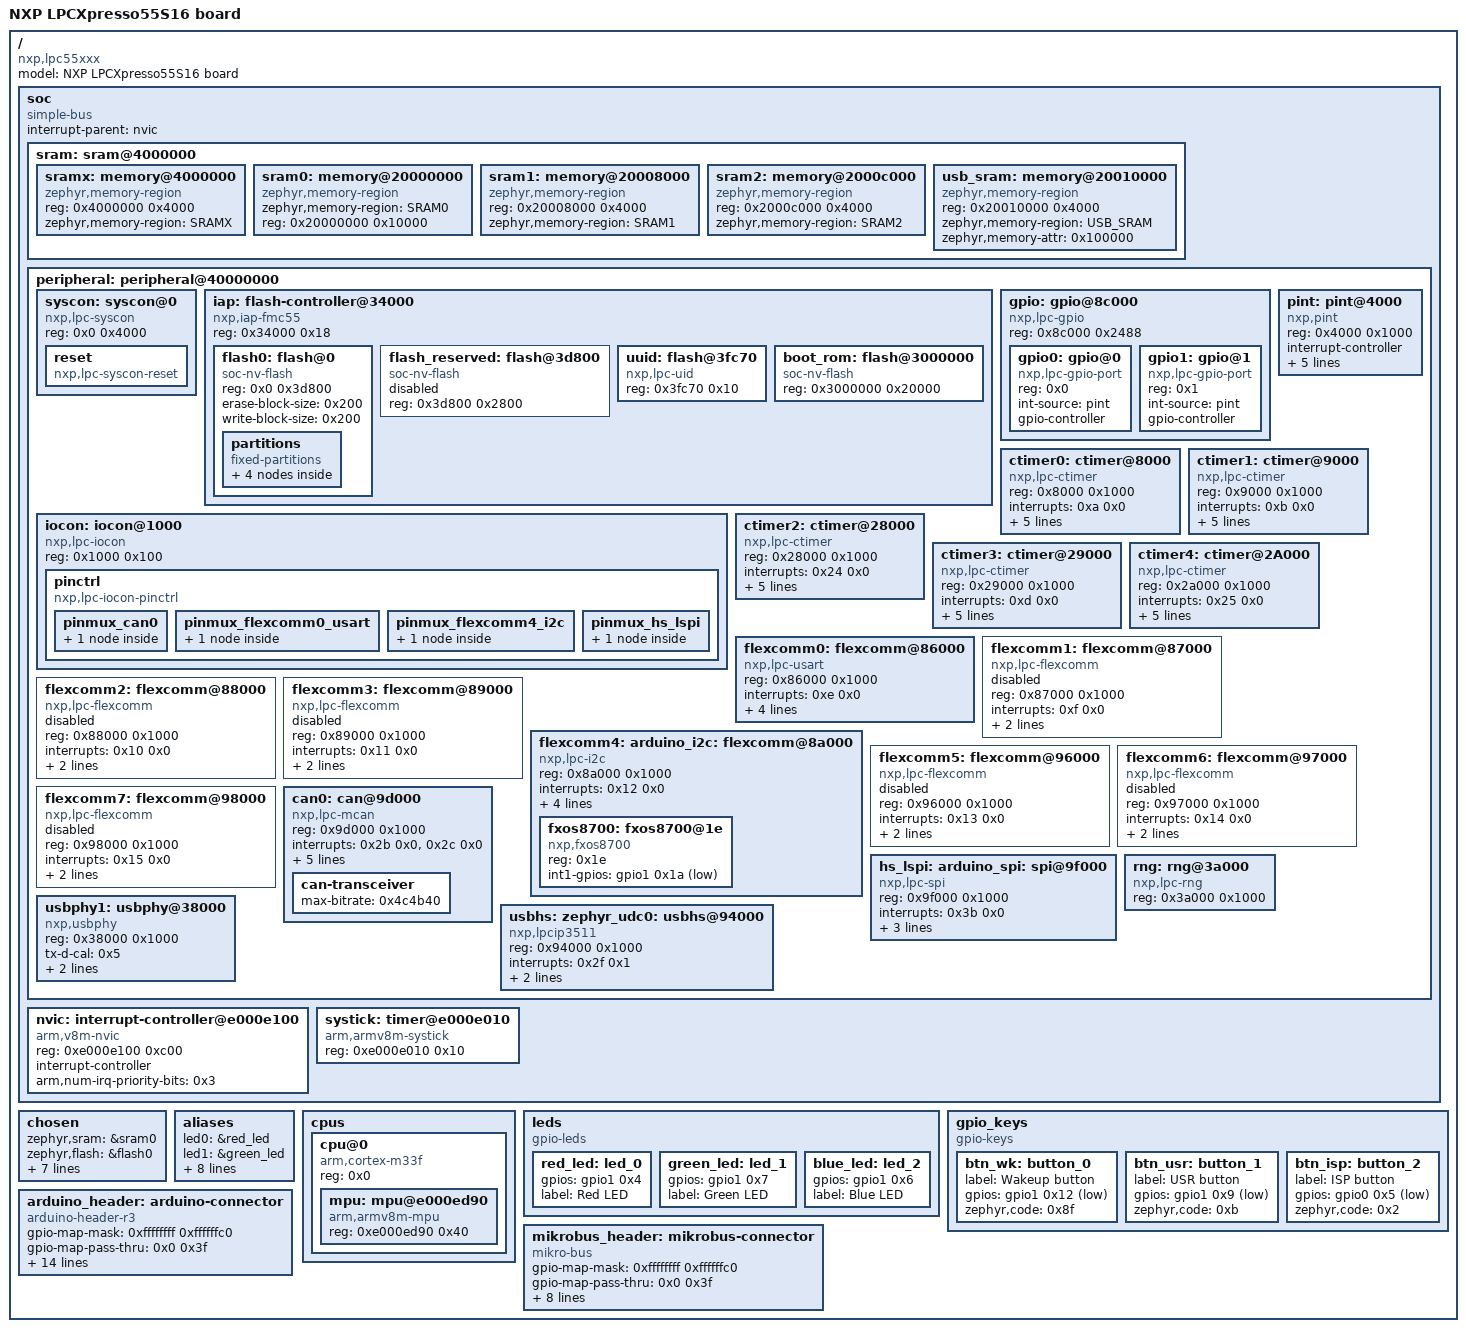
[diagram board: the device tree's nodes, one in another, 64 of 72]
/dts-v1/;

/* node '/' defined in zephyr/dts/arm/nxp/nxp_lpc55S16_ns.dtsi:7 */
/ {
	#address-cells = < 0x1 >;            /* in zephyr/dts/common/skeleton.dtsi:10 */
	#size-cells = < 0x1 >;               /* in zephyr/dts/common/skeleton.dtsi:11 */
	model = "NXP LPCXpresso55S16 board"; /* in zephyr/boards/nxp/lpcxpresso55s16/lpcxpresso55s16.dts:14 */
	compatible = "nxp,lpc55xxx",
	             "nxp,lpc";              /* in zephyr/boards/nxp/lpcxpresso55s16/lpcxpresso55s16.dts:15 */

	/* node '/soc' defined in zephyr/dts/arm/nxp/nxp_lpc55S16_ns.dtsi:8 */
	soc {
		#address-cells = < 0x1 >;     /* in zephyr/dts/arm/armv8-m.dtsi:7 */
		#size-cells = < 0x1 >;        /* in zephyr/dts/arm/armv8-m.dtsi:8 */
		compatible = "simple-bus";    /* in zephyr/dts/arm/armv8-m.dtsi:9 */
		interrupt-parent = < &nvic >; /* in zephyr/dts/arm/armv8-m.dtsi:10 */
		ranges;                       /* in zephyr/dts/arm/armv8-m.dtsi:11 */

		/* node '/soc/sram@4000000' defined in zephyr/dts/arm/nxp/nxp_lpc55S16_ns.dtsi:9 */
		sram: sram@4000000 {
			ranges = < 0x4000000 0x4000000 0x20000000 >; /* in zephyr/dts/arm/nxp/nxp_lpc55S16_ns.dtsi:10 */
			#address-cells = < 0x1 >;                    /* in zephyr/dts/arm/nxp/nxp_lpc55S1x_common.dtsi:36 */
			#size-cells = < 0x1 >;                       /* in zephyr/dts/arm/nxp/nxp_lpc55S1x_common.dtsi:37 */

			/* node '/soc/sram@4000000/memory@4000000' defined in zephyr/dts/arm/nxp/nxp_lpc55S1x_common.dtsi:39 */
			sramx: memory@4000000 {
				compatible = "zephyr,memory-region",
				             "mmio-sram";            /* in zephyr/dts/arm/nxp/nxp_lpc55S1x_common.dtsi:40 */
				reg = < 0x4000000 0x4000 >;          /* in zephyr/dts/arm/nxp/nxp_lpc55S1x_common.dtsi:41 */
				zephyr,memory-region = "SRAMX";      /* in zephyr/dts/arm/nxp/nxp_lpc55S1x_common.dtsi:42 */
			};

			/* node '/soc/sram@4000000/memory@20000000' defined in zephyr/dts/arm/nxp/nxp_lpc55S1x_common.dtsi:45 */
			sram0: memory@20000000 {
				compatible = "zephyr,memory-region",
				             "mmio-sram";            /* in zephyr/dts/arm/nxp/nxp_lpc55S1x_common.dtsi:46 */
				zephyr,memory-region = "SRAM0";      /* in zephyr/dts/arm/nxp/nxp_lpc55S1x_common.dtsi:48 */
				reg = < 0x20000000 0x10000 >;        /* in zephyr/boards/nxp/lpcxpresso55s16/lpcxpresso55s16.dts:24 */
			};

			/* node '/soc/sram@4000000/memory@20008000' defined in zephyr/dts/arm/nxp/nxp_lpc55S1x_common.dtsi:51 */
			sram1: memory@20008000 {
				compatible = "zephyr,memory-region",
				             "mmio-sram";            /* in zephyr/dts/arm/nxp/nxp_lpc55S1x_common.dtsi:52 */
				reg = < 0x20008000 0x4000 >;         /* in zephyr/dts/arm/nxp/nxp_lpc55S1x_common.dtsi:53 */
				zephyr,memory-region = "SRAM1";      /* in zephyr/dts/arm/nxp/nxp_lpc55S1x_common.dtsi:54 */
			};

			/* node '/soc/sram@4000000/memory@2000c000' defined in zephyr/dts/arm/nxp/nxp_lpc55S1x_common.dtsi:57 */
			sram2: memory@2000c000 {
				compatible = "zephyr,memory-region",
				             "mmio-sram";            /* in zephyr/dts/arm/nxp/nxp_lpc55S1x_common.dtsi:58 */
				reg = < 0x2000c000 0x4000 >;         /* in zephyr/dts/arm/nxp/nxp_lpc55S1x_common.dtsi:59 */
				zephyr,memory-region = "SRAM2";      /* in zephyr/dts/arm/nxp/nxp_lpc55S1x_common.dtsi:60 */
			};

			/* node '/soc/sram@4000000/memory@20010000' defined in zephyr/dts/arm/nxp/nxp_lpc55S1x_common.dtsi:63 */
			usb_sram: memory@20010000 {
				compatible = "zephyr,memory-region",
				             "mmio-sram";            /* in zephyr/dts/arm/nxp/nxp_lpc55S1x_common.dtsi:65 */
				reg = < 0x20010000 0x4000 >;         /* in zephyr/dts/arm/nxp/nxp_lpc55S1x_common.dtsi:66 */
				zephyr,memory-region = "USB_SRAM";   /* in zephyr/dts/arm/nxp/nxp_lpc55S1x_common.dtsi:67 */
				zephyr,memory-attr = < 0x100000 >;   /* in zephyr/dts/arm/nxp/nxp_lpc55S1x_common.dtsi:68 */
			};
		};

		/* node '/soc/peripheral@40000000' defined in zephyr/dts/arm/nxp/nxp_lpc55S16_ns.dtsi:13 */
		peripheral: peripheral@40000000 {
			ranges = < 0x0 0x40000000 0x10000000 >; /* in zephyr/dts/arm/nxp/nxp_lpc55S16_ns.dtsi:14 */
			#address-cells = < 0x1 >;               /* in zephyr/dts/arm/nxp/nxp_lpc55S1x_common.dtsi:73 */
			#size-cells = < 0x1 >;                  /* in zephyr/dts/arm/nxp/nxp_lpc55S1x_common.dtsi:74 */

			/* node '/soc/peripheral@40000000/syscon@0' defined in zephyr/dts/arm/nxp/nxp_lpc55S1x_common.dtsi:76 */
			syscon: syscon@0 {
				compatible = "nxp,lpc-syscon"; /* in zephyr/dts/arm/nxp/nxp_lpc55S1x_common.dtsi:77 */
				reg = < 0x0 0x4000 >;          /* in zephyr/dts/arm/nxp/nxp_lpc55S1x_common.dtsi:78 */
				#clock-cells = < 0x1 >;        /* in zephyr/dts/arm/nxp/nxp_lpc55S1x_common.dtsi:79 */
				phandle = < 0x2 >;             /* in zephyr/dts/arm/nxp/nxp_lpc55S1x_common.dtsi:171 */

				/* node '/soc/peripheral@40000000/syscon@0/reset' defined in zephyr/dts/arm/nxp/nxp_lpc55S1x_common.dtsi:81 */
				reset: reset {
					compatible = "nxp,lpc-syscon-reset"; /* in zephyr/dts/arm/nxp/nxp_lpc55S1x_common.dtsi:82 */
					#reset-cells = < 0x1 >;              /* in zephyr/dts/arm/nxp/nxp_lpc55S1x_common.dtsi:83 */
					phandle = < 0x3 >;                   /* in zephyr/dts/arm/nxp/nxp_lpc55S1x_common.dtsi:230 */
				};
			};

			/* node '/soc/peripheral@40000000/flash-controller@34000' defined in zephyr/dts/arm/nxp/nxp_lpc55S1x_common.dtsi:87 */
			iap: flash-controller@34000 {
				compatible = "nxp,iap-fmc55"; /* in zephyr/dts/arm/nxp/nxp_lpc55S1x_common.dtsi:88 */
				reg = < 0x34000 0x18 >;       /* in zephyr/dts/arm/nxp/nxp_lpc55S1x_common.dtsi:89 */
				#address-cells = < 0x1 >;     /* in zephyr/dts/arm/nxp/nxp_lpc55S1x_common.dtsi:90 */
				#size-cells = < 0x1 >;        /* in zephyr/dts/arm/nxp/nxp_lpc55S1x_common.dtsi:91 */
				status = "okay";              /* in zephyr/dts/arm/nxp/nxp_lpc55S16_ns.dtsi:22 */

				/* node '/soc/peripheral@40000000/flash-controller@34000/flash@0' defined in zephyr/dts/arm/nxp/nxp_lpc55S1x_common.dtsi:94 */
				flash0: flash@0 {
					compatible = "soc-nv-flash";  /* in zephyr/dts/arm/nxp/nxp_lpc55S1x_common.dtsi:95 */
					reg = < 0x0 0x3d800 >;        /* in zephyr/dts/arm/nxp/nxp_lpc55S1x_common.dtsi:96 */
					erase-block-size = < 0x200 >; /* in zephyr/dts/arm/nxp/nxp_lpc55S1x_common.dtsi:97 */
					write-block-size = < 0x200 >; /* in zephyr/dts/arm/nxp/nxp_lpc55S1x_common.dtsi:98 */

					/* node '/soc/peripheral@40000000/flash-controller@34000/flash@0/partitions' defined in zephyr/boards/nxp/lpcxpresso55s16/lpcxpresso55s16_common.dtsi:194 */
					partitions {
						compatible = "fixed-partitions"; /* in zephyr/boards/nxp/lpcxpresso55s16/lpcxpresso55s16_common.dtsi:195 */
						#address-cells = < 0x1 >;        /* in zephyr/boards/nxp/lpcxpresso55s16/lpcxpresso55s16_common.dtsi:196 */
						#size-cells = < 0x1 >;           /* in zephyr/boards/nxp/lpcxpresso55s16/lpcxpresso55s16_common.dtsi:197 */

						/* node '/soc/peripheral@40000000/flash-controller@34000/flash@0/partitions/partition@0' defined in zephyr/boards/nxp/lpcxpresso55s16/lpcxpresso55s16_common.dtsi:199 */
						boot_partition: partition@0 {
							label = "mcuboot";    /* in zephyr/boards/nxp/lpcxpresso55s16/lpcxpresso55s16_common.dtsi:200 */
							reg = < 0x0 0x8000 >; /* in zephyr/boards/nxp/lpcxpresso55s16/lpcxpresso55s16_common.dtsi:201 */
						};

						/* node '/soc/peripheral@40000000/flash-controller@34000/flash@0/partitions/partition@8000' defined in zephyr/boards/nxp/lpcxpresso55s16/lpcxpresso55s16_common.dtsi:204 */
						slot0_partition: partition@8000 {
							label = "image-0";        /* in zephyr/boards/nxp/lpcxpresso55s16/lpcxpresso55s16_common.dtsi:205 */
							reg = < 0x8000 0x18000 >; /* in zephyr/boards/nxp/lpcxpresso55s16/lpcxpresso55s16_common.dtsi:206 */
						};

						/* node '/soc/peripheral@40000000/flash-controller@34000/flash@0/partitions/partition@20000' defined in zephyr/boards/nxp/lpcxpresso55s16/lpcxpresso55s16_common.dtsi:209 */
						slot1_partition: partition@20000 {
							label = "image-1";         /* in zephyr/boards/nxp/lpcxpresso55s16/lpcxpresso55s16_common.dtsi:210 */
							reg = < 0x20000 0x18000 >; /* in zephyr/boards/nxp/lpcxpresso55s16/lpcxpresso55s16_common.dtsi:211 */
						};

						/* node '/soc/peripheral@40000000/flash-controller@34000/flash@0/partitions/partition@38000' defined in zephyr/boards/nxp/lpcxpresso55s16/lpcxpresso55s16_common.dtsi:214 */
						storage_partition: partition@38000 {
							label = "storage";        /* in zephyr/boards/nxp/lpcxpresso55s16/lpcxpresso55s16_common.dtsi:215 */
							reg = < 0x38000 0x5000 >; /* in zephyr/boards/nxp/lpcxpresso55s16/lpcxpresso55s16_common.dtsi:216 */
						};
					};
				};

				/* node '/soc/peripheral@40000000/flash-controller@34000/flash@3d800' defined in zephyr/dts/arm/nxp/nxp_lpc55S1x_common.dtsi:101 */
				flash_reserved: flash@3d800 {
					compatible = "soc-nv-flash"; /* in zephyr/dts/arm/nxp/nxp_lpc55S1x_common.dtsi:102 */
					reg = < 0x3d800 0x2800 >;    /* in zephyr/dts/arm/nxp/nxp_lpc55S1x_common.dtsi:103 */
					status = "disabled";         /* in zephyr/dts/arm/nxp/nxp_lpc55S1x_common.dtsi:104 */
				};

				/* node '/soc/peripheral@40000000/flash-controller@34000/flash@3fc70' defined in zephyr/dts/arm/nxp/nxp_lpc55S1x_common.dtsi:107 */
				uuid: flash@3fc70 {
					compatible = "nxp,lpc-uid"; /* in zephyr/dts/arm/nxp/nxp_lpc55S1x_common.dtsi:108 */
					reg = < 0x3fc70 0x10 >;     /* in zephyr/dts/arm/nxp/nxp_lpc55S1x_common.dtsi:109 */
				};

				/* node '/soc/peripheral@40000000/flash-controller@34000/flash@3000000' defined in zephyr/dts/arm/nxp/nxp_lpc55S1x_common.dtsi:112 */
				boot_rom: flash@3000000 {
					compatible = "soc-nv-flash"; /* in zephyr/dts/arm/nxp/nxp_lpc55S1x_common.dtsi:113 */
					reg = < 0x3000000 0x20000 >; /* in zephyr/dts/arm/nxp/nxp_lpc55S1x_common.dtsi:114 */
				};
			};

			/* node '/soc/peripheral@40000000/iocon@1000' defined in zephyr/dts/arm/nxp/nxp_lpc55S1x_common.dtsi:118 */
			iocon: iocon@1000 {
				compatible = "nxp,lpc-iocon";  /* in zephyr/dts/arm/nxp/nxp_lpc55S1x_common.dtsi:119 */
				reg = < 0x1000 0x100 >;        /* in zephyr/dts/arm/nxp/nxp_lpc55S1x_common.dtsi:120 */
				#address-cells = < 0x1 >;      /* in zephyr/dts/arm/nxp/nxp_lpc55S1x_common.dtsi:121 */
				#size-cells = < 0x1 >;         /* in zephyr/dts/arm/nxp/nxp_lpc55S1x_common.dtsi:122 */
				ranges = < 0x0 0x1000 0x100 >; /* in zephyr/dts/arm/nxp/nxp_lpc55S1x_common.dtsi:123 */

				/* node '/soc/peripheral@40000000/iocon@1000/pinctrl' defined in zephyr/dts/arm/nxp/nxp_lpc55S1x_common.dtsi:125 */
				pinctrl: pinctrl {
					compatible = "nxp,lpc-iocon-pinctrl"; /* in zephyr/dts/arm/nxp/nxp_lpc55S1x_common.dtsi:126 */

					/* node '/soc/peripheral@40000000/iocon@1000/pinctrl/pinmux_can0' defined in zephyr/boards/nxp/lpcxpresso55s16/lpcxpresso55s16-pinctrl.dtsi:12 */
					pinmux_can0: pinmux_can0 {
						phandle = < 0x7 >; /* in zephyr/boards/nxp/lpcxpresso55s16/lpcxpresso55s16_common.dtsi:159 */

						/* node '/soc/peripheral@40000000/iocon@1000/pinctrl/pinmux_can0/group0' defined in zephyr/boards/nxp/lpcxpresso55s16/lpcxpresso55s16-pinctrl.dtsi:13 */
						group0 {
							pinmux = < 0x3600009 >,
							         < 0x3b00009 >; /* in zephyr/boards/nxp/lpcxpresso55s16/lpcxpresso55s16-pinctrl.dtsi:14 */
							slew-rate = "standard"; /* in zephyr/boards/nxp/lpcxpresso55s16/lpcxpresso55s16-pinctrl.dtsi:16 */
						};
					};

					/* node '/soc/peripheral@40000000/iocon@1000/pinctrl/pinmux_flexcomm0_usart' defined in zephyr/boards/nxp/lpcxpresso55s16/lpcxpresso55s16-pinctrl.dtsi:20 */
					pinmux_flexcomm0_usart: pinmux_flexcomm0_usart {
						phandle = < 0x4 >; /* in zephyr/boards/nxp/lpcxpresso55s16/lpcxpresso55s16_common.dtsi:137 */

						/* node '/soc/peripheral@40000000/iocon@1000/pinctrl/pinmux_flexcomm0_usart/group0' defined in zephyr/boards/nxp/lpcxpresso55s16/lpcxpresso55s16-pinctrl.dtsi:21 */
						group0 {
							pinmux = < 0x1d00001 >,
							         < 0x1e00001 >; /* in zephyr/boards/nxp/lpcxpresso55s16/lpcxpresso55s16-pinctrl.dtsi:22 */
							slew-rate = "standard"; /* in zephyr/boards/nxp/lpcxpresso55s16/lpcxpresso55s16-pinctrl.dtsi:24 */
						};
					};

					/* node '/soc/peripheral@40000000/iocon@1000/pinctrl/pinmux_flexcomm4_i2c' defined in zephyr/boards/nxp/lpcxpresso55s16/lpcxpresso55s16-pinctrl.dtsi:28 */
					pinmux_flexcomm4_i2c: pinmux_flexcomm4_i2c {
						phandle = < 0x5 >; /* in zephyr/boards/nxp/lpcxpresso55s16/lpcxpresso55s16_common.dtsi:147 */

						/* node '/soc/peripheral@40000000/iocon@1000/pinctrl/pinmux_flexcomm4_i2c/group0' defined in zephyr/boards/nxp/lpcxpresso55s16/lpcxpresso55s16-pinctrl.dtsi:29 */
						group0 {
							pinmux = < 0x3400005 >,
							         < 0x3500005 >; /* in zephyr/boards/nxp/lpcxpresso55s16/lpcxpresso55s16-pinctrl.dtsi:30 */
							slew-rate = "standard"; /* in zephyr/boards/nxp/lpcxpresso55s16/lpcxpresso55s16-pinctrl.dtsi:32 */
						};
					};

					/* node '/soc/peripheral@40000000/iocon@1000/pinctrl/pinmux_hs_lspi' defined in zephyr/boards/nxp/lpcxpresso55s16/lpcxpresso55s16-pinctrl.dtsi:36 */
					pinmux_hs_lspi: pinmux_hs_lspi {
						phandle = < 0x8 >; /* in zephyr/boards/nxp/lpcxpresso55s16/lpcxpresso55s16_common.dtsi:169 */

						/* node '/soc/peripheral@40000000/iocon@1000/pinctrl/pinmux_hs_lspi/group0' defined in zephyr/boards/nxp/lpcxpresso55s16/lpcxpresso55s16-pinctrl.dtsi:37 */
						group0 {
							pinmux = < 0x1a00009 >,
							         < 0x2100005 >,
							         < 0x2200006 >,
							         < 0x2300006 >; /* in zephyr/boards/nxp/lpcxpresso55s16/lpcxpresso55s16-pinctrl.dtsi:38 */
							bias-pull-up;           /* in zephyr/boards/nxp/lpcxpresso55s16/lpcxpresso55s16-pinctrl.dtsi:42 */
							slew-rate = "standard"; /* in zephyr/boards/nxp/lpcxpresso55s16/lpcxpresso55s16-pinctrl.dtsi:43 */
						};
					};
				};
			};

			/* node '/soc/peripheral@40000000/gpio@8c000' defined in zephyr/dts/arm/nxp/nxp_lpc55S1x_common.dtsi:130 */
			gpio: gpio@8c000 {
				compatible = "nxp,lpc-gpio"; /* in zephyr/dts/arm/nxp/nxp_lpc55S1x_common.dtsi:131 */
				reg = < 0x8c000 0x2488 >;    /* in zephyr/dts/arm/nxp/nxp_lpc55S1x_common.dtsi:132 */
				#address-cells = < 0x1 >;    /* in zephyr/dts/arm/nxp/nxp_lpc55S1x_common.dtsi:133 */
				#size-cells = < 0x0 >;       /* in zephyr/dts/arm/nxp/nxp_lpc55S1x_common.dtsi:134 */

				/* node '/soc/peripheral@40000000/gpio@8c000/gpio@0' defined in zephyr/dts/arm/nxp/nxp_lpc55S1x_common.dtsi:136 */
				gpio0: gpio@0 {
					compatible = "nxp,lpc-gpio-port"; /* in zephyr/dts/arm/nxp/nxp_lpc55S1x_common.dtsi:137 */
					reg = < 0x0 >;                    /* in zephyr/dts/arm/nxp/nxp_lpc55S1x_common.dtsi:138 */
					int-source = "pint";              /* in zephyr/dts/arm/nxp/nxp_lpc55S1x_common.dtsi:139 */
					gpio-controller;                  /* in zephyr/dts/arm/nxp/nxp_lpc55S1x_common.dtsi:140 */
					#gpio-cells = < 0x2 >;            /* in zephyr/dts/arm/nxp/nxp_lpc55S1x_common.dtsi:141 */
					phandle = < 0xa >;                /* in zephyr/boards/nxp/lpcxpresso55s16/lpcxpresso55s16_common.dtsi:74 */
				};

				/* node '/soc/peripheral@40000000/gpio@8c000/gpio@1' defined in zephyr/dts/arm/nxp/nxp_lpc55S1x_common.dtsi:144 */
				gpio1: gpio@1 {
					compatible = "nxp,lpc-gpio-port"; /* in zephyr/dts/arm/nxp/nxp_lpc55S1x_common.dtsi:145 */
					reg = < 0x1 >;                    /* in zephyr/dts/arm/nxp/nxp_lpc55S1x_common.dtsi:146 */
					int-source = "pint";              /* in zephyr/dts/arm/nxp/nxp_lpc55S1x_common.dtsi:147 */
					gpio-controller;                  /* in zephyr/dts/arm/nxp/nxp_lpc55S1x_common.dtsi:148 */
					#gpio-cells = < 0x2 >;            /* in zephyr/dts/arm/nxp/nxp_lpc55S1x_common.dtsi:149 */
					phandle = < 0x6 >;                /* in zephyr/boards/nxp/lpcxpresso55s16/lpcxpresso55s16_common.dtsi:153 */
				};
			};

			/* node '/soc/peripheral@40000000/pint@4000' defined in zephyr/dts/arm/nxp/nxp_lpc55S1x_common.dtsi:153 */
			pint: pint@4000 {
				compatible = "nxp,pint";    /* in zephyr/dts/arm/nxp/nxp_lpc55S1x_common.dtsi:154 */
				reg = < 0x4000 0x1000 >;    /* in zephyr/dts/arm/nxp/nxp_lpc55S1x_common.dtsi:155 */
				interrupt-controller;       /* in zephyr/dts/arm/nxp/nxp_lpc55S1x_common.dtsi:156 */
				#interrupt-cells = < 0x1 >; /* in zephyr/dts/arm/nxp/nxp_lpc55S1x_common.dtsi:157 */
				#address-cells = < 0x0 >;   /* in zephyr/dts/arm/nxp/nxp_lpc55S1x_common.dtsi:158 */
				interrupts = < 0x4 0x2 >,
				             < 0x5 0x2 >,
				             < 0x6 0x2 >,
				             < 0x7 0x2 >,
				             < 0x20 0x2 >,
				             < 0x21 0x2 >,
				             < 0x22 0x2 >,
				             < 0x23 0x2 >;  /* in zephyr/dts/arm/nxp/nxp_lpc55S1x_common.dtsi:159 */
				num-lines = < 0x8 >;        /* in zephyr/dts/arm/nxp/nxp_lpc55S1x_common.dtsi:161 */
				num-inputs = < 0x40 >;      /* in zephyr/dts/arm/nxp/nxp_lpc55S1x_common.dtsi:162 */
			};

			/* node '/soc/peripheral@40000000/ctimer@8000' defined in zephyr/dts/arm/nxp/nxp_lpc55S1x_common.dtsi:165 */
			ctimer0: ctimer@8000 {
				compatible = "nxp,lpc-ctimer"; /* in zephyr/dts/arm/nxp/nxp_lpc55S1x_common.dtsi:166 */
				reg = < 0x8000 0x1000 >;       /* in zephyr/dts/arm/nxp/nxp_lpc55S1x_common.dtsi:167 */
				interrupts = < 0xa 0x0 >;      /* in zephyr/dts/arm/nxp/nxp_lpc55S1x_common.dtsi:168 */
				clk-source = < 0x3 >;          /* in zephyr/dts/arm/nxp/nxp_lpc55S1x_common.dtsi:170 */
				clocks = < &syscon 0x0 >;      /* in zephyr/dts/arm/nxp/nxp_lpc55S1x_common.dtsi:171 */
				mode = < 0x0 >;                /* in zephyr/dts/arm/nxp/nxp_lpc55S1x_common.dtsi:172 */
				input = < 0x0 >;               /* in zephyr/dts/arm/nxp/nxp_lpc55S1x_common.dtsi:173 */
				prescale = < 0x0 >;            /* in zephyr/dts/arm/nxp/nxp_lpc55S1x_common.dtsi:174 */
				status = "okay";               /* in zephyr/boards/nxp/lpcxpresso55s16/lpcxpresso55s16_common.dtsi:174 */
			};

			/* node '/soc/peripheral@40000000/ctimer@9000' defined in zephyr/dts/arm/nxp/nxp_lpc55S1x_common.dtsi:177 */
			ctimer1: ctimer@9000 {
				compatible = "nxp,lpc-ctimer"; /* in zephyr/dts/arm/nxp/nxp_lpc55S1x_common.dtsi:178 */
				reg = < 0x9000 0x1000 >;       /* in zephyr/dts/arm/nxp/nxp_lpc55S1x_common.dtsi:179 */
				interrupts = < 0xb 0x0 >;      /* in zephyr/dts/arm/nxp/nxp_lpc55S1x_common.dtsi:180 */
				clk-source = < 0x3 >;          /* in zephyr/dts/arm/nxp/nxp_lpc55S1x_common.dtsi:182 */
				clocks = < &syscon 0x1 >;      /* in zephyr/dts/arm/nxp/nxp_lpc55S1x_common.dtsi:183 */
				mode = < 0x0 >;                /* in zephyr/dts/arm/nxp/nxp_lpc55S1x_common.dtsi:184 */
				input = < 0x0 >;               /* in zephyr/dts/arm/nxp/nxp_lpc55S1x_common.dtsi:185 */
				prescale = < 0x0 >;            /* in zephyr/dts/arm/nxp/nxp_lpc55S1x_common.dtsi:186 */
				status = "okay";               /* in zephyr/boards/nxp/lpcxpresso55s16/lpcxpresso55s16_common.dtsi:178 */
			};

			/* node '/soc/peripheral@40000000/ctimer@28000' defined in zephyr/dts/arm/nxp/nxp_lpc55S1x_common.dtsi:189 */
			ctimer2: ctimer@28000 {
				compatible = "nxp,lpc-ctimer"; /* in zephyr/dts/arm/nxp/nxp_lpc55S1x_common.dtsi:190 */
				reg = < 0x28000 0x1000 >;      /* in zephyr/dts/arm/nxp/nxp_lpc55S1x_common.dtsi:191 */
				interrupts = < 0x24 0x0 >;     /* in zephyr/dts/arm/nxp/nxp_lpc55S1x_common.dtsi:192 */
				clk-source = < 0x3 >;          /* in zephyr/dts/arm/nxp/nxp_lpc55S1x_common.dtsi:194 */
				clocks = < &syscon 0x2 >;      /* in zephyr/dts/arm/nxp/nxp_lpc55S1x_common.dtsi:195 */
				mode = < 0x0 >;                /* in zephyr/dts/arm/nxp/nxp_lpc55S1x_common.dtsi:196 */
				input = < 0x0 >;               /* in zephyr/dts/arm/nxp/nxp_lpc55S1x_common.dtsi:197 */
				prescale = < 0x0 >;            /* in zephyr/dts/arm/nxp/nxp_lpc55S1x_common.dtsi:198 */
				status = "okay";               /* in zephyr/boards/nxp/lpcxpresso55s16/lpcxpresso55s16_common.dtsi:182 */
			};

			/* node '/soc/peripheral@40000000/ctimer@29000' defined in zephyr/dts/arm/nxp/nxp_lpc55S1x_common.dtsi:201 */
			ctimer3: ctimer@29000 {
				compatible = "nxp,lpc-ctimer"; /* in zephyr/dts/arm/nxp/nxp_lpc55S1x_common.dtsi:202 */
				reg = < 0x29000 0x1000 >;      /* in zephyr/dts/arm/nxp/nxp_lpc55S1x_common.dtsi:203 */
				interrupts = < 0xd 0x0 >;      /* in zephyr/dts/arm/nxp/nxp_lpc55S1x_common.dtsi:204 */
				clk-source = < 0x3 >;          /* in zephyr/dts/arm/nxp/nxp_lpc55S1x_common.dtsi:206 */
				clocks = < &syscon 0x3 >;      /* in zephyr/dts/arm/nxp/nxp_lpc55S1x_common.dtsi:207 */
				mode = < 0x0 >;                /* in zephyr/dts/arm/nxp/nxp_lpc55S1x_common.dtsi:208 */
				input = < 0x0 >;               /* in zephyr/dts/arm/nxp/nxp_lpc55S1x_common.dtsi:209 */
				prescale = < 0x0 >;            /* in zephyr/dts/arm/nxp/nxp_lpc55S1x_common.dtsi:210 */
				status = "okay";               /* in zephyr/boards/nxp/lpcxpresso55s16/lpcxpresso55s16_common.dtsi:186 */
			};

			/* node '/soc/peripheral@40000000/ctimer@2A000' defined in zephyr/dts/arm/nxp/nxp_lpc55S1x_common.dtsi:213 */
			ctimer4: ctimer@2A000 {
				compatible = "nxp,lpc-ctimer"; /* in zephyr/dts/arm/nxp/nxp_lpc55S1x_common.dtsi:214 */
				reg = < 0x2a000 0x1000 >;      /* in zephyr/dts/arm/nxp/nxp_lpc55S1x_common.dtsi:215 */
				interrupts = < 0x25 0x0 >;     /* in zephyr/dts/arm/nxp/nxp_lpc55S1x_common.dtsi:216 */
				clk-source = < 0x3 >;          /* in zephyr/dts/arm/nxp/nxp_lpc55S1x_common.dtsi:218 */
				clocks = < &syscon 0x4 >;      /* in zephyr/dts/arm/nxp/nxp_lpc55S1x_common.dtsi:219 */
				mode = < 0x0 >;                /* in zephyr/dts/arm/nxp/nxp_lpc55S1x_common.dtsi:220 */
				input = < 0x0 >;               /* in zephyr/dts/arm/nxp/nxp_lpc55S1x_common.dtsi:221 */
				prescale = < 0x0 >;            /* in zephyr/dts/arm/nxp/nxp_lpc55S1x_common.dtsi:222 */
				status = "okay";               /* in zephyr/boards/nxp/lpcxpresso55s16/lpcxpresso55s16_common.dtsi:190 */
			};

			/* node '/soc/peripheral@40000000/flexcomm@86000' defined in zephyr/dts/arm/nxp/nxp_lpc55S1x_common.dtsi:225 */
			flexcomm0: flexcomm@86000 {
				reg = < 0x86000 0x1000 >;                /* in zephyr/dts/arm/nxp/nxp_lpc55S1x_common.dtsi:227 */
				interrupts = < 0xe 0x0 >;                /* in zephyr/dts/arm/nxp/nxp_lpc55S1x_common.dtsi:228 */
				clocks = < &syscon 0x100 >;              /* in zephyr/dts/arm/nxp/nxp_lpc55S1x_common.dtsi:229 */
				resets = < &reset 0x1000b >;             /* in zephyr/dts/arm/nxp/nxp_lpc55S1x_common.dtsi:230 */
				status = "okay";                         /* in zephyr/boards/nxp/lpcxpresso55s16/lpcxpresso55s16_common.dtsi:134 */
				compatible = "nxp,lpc-usart";            /* in zephyr/boards/nxp/lpcxpresso55s16/lpcxpresso55s16_common.dtsi:135 */
				current-speed = < 0x1c200 >;             /* in zephyr/boards/nxp/lpcxpresso55s16/lpcxpresso55s16_common.dtsi:136 */
				pinctrl-0 = < &pinmux_flexcomm0_usart >; /* in zephyr/boards/nxp/lpcxpresso55s16/lpcxpresso55s16_common.dtsi:137 */
				pinctrl-names = "default";               /* in zephyr/boards/nxp/lpcxpresso55s16/lpcxpresso55s16_common.dtsi:138 */
			};

			/* node '/soc/peripheral@40000000/flexcomm@87000' defined in zephyr/dts/arm/nxp/nxp_lpc55S1x_common.dtsi:234 */
			flexcomm1: flexcomm@87000 {
				compatible = "nxp,lpc-flexcomm"; /* in zephyr/dts/arm/nxp/nxp_lpc55S1x_common.dtsi:235 */
				reg = < 0x87000 0x1000 >;        /* in zephyr/dts/arm/nxp/nxp_lpc55S1x_common.dtsi:236 */
				interrupts = < 0xf 0x0 >;        /* in zephyr/dts/arm/nxp/nxp_lpc55S1x_common.dtsi:237 */
				clocks = < &syscon 0x101 >;      /* in zephyr/dts/arm/nxp/nxp_lpc55S1x_common.dtsi:238 */
				resets = < &reset 0x1000c >;     /* in zephyr/dts/arm/nxp/nxp_lpc55S1x_common.dtsi:239 */
				status = "disabled";             /* in zephyr/dts/arm/nxp/nxp_lpc55S1x_common.dtsi:240 */
			};

			/* node '/soc/peripheral@40000000/flexcomm@88000' defined in zephyr/dts/arm/nxp/nxp_lpc55S1x_common.dtsi:243 */
			flexcomm2: flexcomm@88000 {
				compatible = "nxp,lpc-flexcomm"; /* in zephyr/dts/arm/nxp/nxp_lpc55S1x_common.dtsi:244 */
				reg = < 0x88000 0x1000 >;        /* in zephyr/dts/arm/nxp/nxp_lpc55S1x_common.dtsi:245 */
				interrupts = < 0x10 0x0 >;       /* in zephyr/dts/arm/nxp/nxp_lpc55S1x_common.dtsi:246 */
				clocks = < &syscon 0x102 >;      /* in zephyr/dts/arm/nxp/nxp_lpc55S1x_common.dtsi:247 */
				resets = < &reset 0x1000d >;     /* in zephyr/dts/arm/nxp/nxp_lpc55S1x_common.dtsi:248 */
				status = "disabled";             /* in zephyr/dts/arm/nxp/nxp_lpc55S1x_common.dtsi:249 */
			};

			/* node '/soc/peripheral@40000000/flexcomm@89000' defined in zephyr/dts/arm/nxp/nxp_lpc55S1x_common.dtsi:252 */
			flexcomm3: flexcomm@89000 {
				compatible = "nxp,lpc-flexcomm"; /* in zephyr/dts/arm/nxp/nxp_lpc55S1x_common.dtsi:253 */
				reg = < 0x89000 0x1000 >;        /* in zephyr/dts/arm/nxp/nxp_lpc55S1x_common.dtsi:254 */
				interrupts = < 0x11 0x0 >;       /* in zephyr/dts/arm/nxp/nxp_lpc55S1x_common.dtsi:255 */
				clocks = < &syscon 0x103 >;      /* in zephyr/dts/arm/nxp/nxp_lpc55S1x_common.dtsi:256 */
				resets = < &reset 0x1000e >;     /* in zephyr/dts/arm/nxp/nxp_lpc55S1x_common.dtsi:257 */
				status = "disabled";             /* in zephyr/dts/arm/nxp/nxp_lpc55S1x_common.dtsi:258 */
			};

			/* node '/soc/peripheral@40000000/flexcomm@8a000' defined in zephyr/dts/arm/nxp/nxp_lpc55S1x_common.dtsi:261 */
			flexcomm4: arduino_i2c: mikrobus_i2c: flexcomm@8a000 {
				reg = < 0x8a000 0x1000 >;              /* in zephyr/dts/arm/nxp/nxp_lpc55S1x_common.dtsi:263 */
				interrupts = < 0x12 0x0 >;             /* in zephyr/dts/arm/nxp/nxp_lpc55S1x_common.dtsi:264 */
				clocks = < &syscon 0x104 >;            /* in zephyr/dts/arm/nxp/nxp_lpc55S1x_common.dtsi:265 */
				resets = < &reset 0x1000f >;           /* in zephyr/dts/arm/nxp/nxp_lpc55S1x_common.dtsi:266 */
				status = "okay";                       /* in zephyr/boards/nxp/lpcxpresso55s16/lpcxpresso55s16_common.dtsi:142 */
				compatible = "nxp,lpc-i2c";            /* in zephyr/boards/nxp/lpcxpresso55s16/lpcxpresso55s16_common.dtsi:143 */
				clock-frequency = < 0x186a0 >;         /* in zephyr/boards/nxp/lpcxpresso55s16/lpcxpresso55s16_common.dtsi:144 */
				#address-cells = < 0x1 >;              /* in zephyr/boards/nxp/lpcxpresso55s16/lpcxpresso55s16_common.dtsi:145 */
				#size-cells = < 0x0 >;                 /* in zephyr/boards/nxp/lpcxpresso55s16/lpcxpresso55s16_common.dtsi:146 */
				pinctrl-0 = < &pinmux_flexcomm4_i2c >; /* in zephyr/boards/nxp/lpcxpresso55s16/lpcxpresso55s16_common.dtsi:147 */
				pinctrl-names = "default";             /* in zephyr/boards/nxp/lpcxpresso55s16/lpcxpresso55s16_common.dtsi:148 */

				/* node '/soc/peripheral@40000000/flexcomm@8a000/fxos8700@1e' defined in zephyr/boards/nxp/lpcxpresso55s16/lpcxpresso55s16_common.dtsi:150 */
				fxos8700: fxos8700@1e {
					compatible = "nxp,fxos8700";       /* in zephyr/boards/nxp/lpcxpresso55s16/lpcxpresso55s16_common.dtsi:151 */
					reg = < 0x1e >;                    /* in zephyr/boards/nxp/lpcxpresso55s16/lpcxpresso55s16_common.dtsi:152 */
					int1-gpios = < &gpio1 0x1a 0x11 >; /* in zephyr/boards/nxp/lpcxpresso55s16/lpcxpresso55s16_common.dtsi:153 */
				};
			};

			/* node '/soc/peripheral@40000000/flexcomm@96000' defined in zephyr/dts/arm/nxp/nxp_lpc55S1x_common.dtsi:270 */
			flexcomm5: flexcomm@96000 {
				compatible = "nxp,lpc-flexcomm"; /* in zephyr/dts/arm/nxp/nxp_lpc55S1x_common.dtsi:271 */
				reg = < 0x96000 0x1000 >;        /* in zephyr/dts/arm/nxp/nxp_lpc55S1x_common.dtsi:272 */
				interrupts = < 0x13 0x0 >;       /* in zephyr/dts/arm/nxp/nxp_lpc55S1x_common.dtsi:273 */
				clocks = < &syscon 0x105 >;      /* in zephyr/dts/arm/nxp/nxp_lpc55S1x_common.dtsi:274 */
				resets = < &reset 0x10010 >;     /* in zephyr/dts/arm/nxp/nxp_lpc55S1x_common.dtsi:275 */
				status = "disabled";             /* in zephyr/dts/arm/nxp/nxp_lpc55S1x_common.dtsi:276 */
			};

			/* node '/soc/peripheral@40000000/flexcomm@97000' defined in zephyr/dts/arm/nxp/nxp_lpc55S1x_common.dtsi:279 */
			flexcomm6: flexcomm@97000 {
				compatible = "nxp,lpc-flexcomm"; /* in zephyr/dts/arm/nxp/nxp_lpc55S1x_common.dtsi:280 */
				reg = < 0x97000 0x1000 >;        /* in zephyr/dts/arm/nxp/nxp_lpc55S1x_common.dtsi:281 */
				interrupts = < 0x14 0x0 >;       /* in zephyr/dts/arm/nxp/nxp_lpc55S1x_common.dtsi:282 */
				clocks = < &syscon 0x106 >;      /* in zephyr/dts/arm/nxp/nxp_lpc55S1x_common.dtsi:283 */
				resets = < &reset 0x10011 >;     /* in zephyr/dts/arm/nxp/nxp_lpc55S1x_common.dtsi:284 */
				status = "disabled";             /* in zephyr/dts/arm/nxp/nxp_lpc55S1x_common.dtsi:285 */
			};

			/* node '/soc/peripheral@40000000/flexcomm@98000' defined in zephyr/dts/arm/nxp/nxp_lpc55S1x_common.dtsi:288 */
			flexcomm7: flexcomm@98000 {
				compatible = "nxp,lpc-flexcomm"; /* in zephyr/dts/arm/nxp/nxp_lpc55S1x_common.dtsi:289 */
				reg = < 0x98000 0x1000 >;        /* in zephyr/dts/arm/nxp/nxp_lpc55S1x_common.dtsi:290 */
				interrupts = < 0x15 0x0 >;       /* in zephyr/dts/arm/nxp/nxp_lpc55S1x_common.dtsi:291 */
				clocks = < &syscon 0x107 >;      /* in zephyr/dts/arm/nxp/nxp_lpc55S1x_common.dtsi:292 */
				resets = < &reset 0x10012 >;     /* in zephyr/dts/arm/nxp/nxp_lpc55S1x_common.dtsi:293 */
				status = "disabled";             /* in zephyr/dts/arm/nxp/nxp_lpc55S1x_common.dtsi:294 */
			};

			/* node '/soc/peripheral@40000000/can@9d000' defined in zephyr/dts/arm/nxp/nxp_lpc55S1x_common.dtsi:297 */
			can0: can@9d000 {
				compatible = "nxp,lpc-mcan";                          /* in zephyr/dts/arm/nxp/nxp_lpc55S1x_common.dtsi:298 */
				reg = < 0x9d000 0x1000 >;                             /* in zephyr/dts/arm/nxp/nxp_lpc55S1x_common.dtsi:299 */
				interrupts = < 0x2b 0x0 >,
				             < 0x2c 0x0 >;                            /* in zephyr/dts/arm/nxp/nxp_lpc55S1x_common.dtsi:300 */
				interrupt-names = "int0",
				                  "int1";                             /* in zephyr/dts/arm/nxp/nxp_lpc55S1x_common.dtsi:301 */
				clocks = < &syscon 0x300 >;                           /* in zephyr/dts/arm/nxp/nxp_lpc55S1x_common.dtsi:302 */
				resets = < &reset 0x10007 >;                          /* in zephyr/dts/arm/nxp/nxp_lpc55S1x_common.dtsi:303 */
				bosch,mram-cfg = < 0x0 0xf 0xf 0x8 0x8 0x0 0xf 0xf >; /* in zephyr/dts/arm/nxp/nxp_lpc55S1x_common.dtsi:304 */
				status = "okay";                                      /* in zephyr/boards/nxp/lpcxpresso55s16/lpcxpresso55s16_common.dtsi:158 */
				pinctrl-0 = < &pinmux_can0 >;                         /* in zephyr/boards/nxp/lpcxpresso55s16/lpcxpresso55s16_common.dtsi:159 */
				pinctrl-names = "default";                            /* in zephyr/boards/nxp/lpcxpresso55s16/lpcxpresso55s16_common.dtsi:160 */

				/* node '/soc/peripheral@40000000/can@9d000/can-transceiver' defined in zephyr/boards/nxp/lpcxpresso55s16/lpcxpresso55s16_common.dtsi:162 */
				can-transceiver {
					max-bitrate = < 0x4c4b40 >; /* in zephyr/boards/nxp/lpcxpresso55s16/lpcxpresso55s16_common.dtsi:163 */
				};
			};

			/* node '/soc/peripheral@40000000/spi@9f000' defined in zephyr/dts/arm/nxp/nxp_lpc55S1x_common.dtsi:308 */
			hs_lspi: arduino_spi: mikrobus_spi: spi@9f000 {
				compatible = "nxp,lpc-spi";      /* in zephyr/dts/arm/nxp/nxp_lpc55S1x_common.dtsi:309 */
				reg = < 0x9f000 0x1000 >;        /* in zephyr/dts/arm/nxp/nxp_lpc55S1x_common.dtsi:310 */
				interrupts = < 0x3b 0x0 >;       /* in zephyr/dts/arm/nxp/nxp_lpc55S1x_common.dtsi:311 */
				clocks = < &syscon 0x10e >;      /* in zephyr/dts/arm/nxp/nxp_lpc55S1x_common.dtsi:312 */
				resets = < &reset 0x2001c >;     /* in zephyr/dts/arm/nxp/nxp_lpc55S1x_common.dtsi:313 */
				#address-cells = < 0x1 >;        /* in zephyr/dts/arm/nxp/nxp_lpc55S1x_common.dtsi:315 */
				#size-cells = < 0x0 >;           /* in zephyr/dts/arm/nxp/nxp_lpc55S1x_common.dtsi:316 */
				status = "okay";                 /* in zephyr/boards/nxp/lpcxpresso55s16/lpcxpresso55s16_common.dtsi:168 */
				pinctrl-0 = < &pinmux_hs_lspi >; /* in zephyr/boards/nxp/lpcxpresso55s16/lpcxpresso55s16_common.dtsi:169 */
				pinctrl-names = "default";       /* in zephyr/boards/nxp/lpcxpresso55s16/lpcxpresso55s16_common.dtsi:170 */
			};

			/* node '/soc/peripheral@40000000/rng@3a000' defined in zephyr/dts/arm/nxp/nxp_lpc55S1x_common.dtsi:319 */
			rng: rng@3a000 {
				compatible = "nxp,lpc-rng"; /* in zephyr/dts/arm/nxp/nxp_lpc55S1x_common.dtsi:320 */
				reg = < 0x3a000 0x1000 >;   /* in zephyr/dts/arm/nxp/nxp_lpc55S1x_common.dtsi:321 */
				status = "okay";            /* in zephyr/dts/arm/nxp/nxp_lpc55S1x_common.dtsi:322 */
			};

			/* node '/soc/peripheral@40000000/usbhs@94000' defined in zephyr/dts/arm/nxp/nxp_lpc55S1x_common.dtsi:325 */
			usbhs: zephyr_udc0: usbhs@94000 {
				compatible = "nxp,lpcip3511";  /* in zephyr/dts/arm/nxp/nxp_lpc55S1x_common.dtsi:326 */
				reg = < 0x94000 0x1000 >;      /* in zephyr/dts/arm/nxp/nxp_lpc55S1x_common.dtsi:327 */
				interrupts = < 0x2f 0x1 >;     /* in zephyr/dts/arm/nxp/nxp_lpc55S1x_common.dtsi:328 */
				num-bidir-endpoints = < 0x6 >; /* in zephyr/dts/arm/nxp/nxp_lpc55S1x_common.dtsi:329 */
				status = "okay";               /* in zephyr/boards/nxp/lpcxpresso55s16/lpcxpresso55s16.dts:28 */
				phy-handle = < &usbphy1 >;     /* in zephyr/boards/nxp/lpcxpresso55s16/lpcxpresso55s16.dts:29 */
			};

			/* node '/soc/peripheral@40000000/usbphy@38000' defined in zephyr/dts/arm/nxp/nxp_lpc55S1x_common.dtsi:333 */
			usbphy1: usbphy@38000 {
				compatible = "nxp,usbphy";   /* in zephyr/dts/arm/nxp/nxp_lpc55S1x_common.dtsi:334 */
				reg = < 0x38000 0x1000 >;    /* in zephyr/dts/arm/nxp/nxp_lpc55S1x_common.dtsi:335 */
				status = "okay";             /* in zephyr/boards/nxp/lpcxpresso55s16/lpcxpresso55s16.dts:33 */
				tx-d-cal = < 0x5 >;          /* in zephyr/boards/nxp/lpcxpresso55s16/lpcxpresso55s16.dts:34 */
				tx-cal-45-dp-ohms = < 0xa >; /* in zephyr/boards/nxp/lpcxpresso55s16/lpcxpresso55s16.dts:35 */
				tx-cal-45-dm-ohms = < 0xa >; /* in zephyr/boards/nxp/lpcxpresso55s16/lpcxpresso55s16.dts:36 */
				phandle = < 0x9 >;           /* in zephyr/boards/nxp/lpcxpresso55s16/lpcxpresso55s16.dts:29 */
			};
		};

		/* node '/soc/interrupt-controller@e000e100' defined in zephyr/dts/arm/armv8-m.dtsi:13 */
		nvic: interrupt-controller@e000e100 {
			#address-cells = < 0x1 >;            /* in zephyr/dts/arm/armv8-m.dtsi:14 */
			compatible = "arm,v8m-nvic";         /* in zephyr/dts/arm/armv8-m.dtsi:15 */
			reg = < 0xe000e100 0xc00 >;          /* in zephyr/dts/arm/armv8-m.dtsi:16 */
			interrupt-controller;                /* in zephyr/dts/arm/armv8-m.dtsi:17 */
			#interrupt-cells = < 0x2 >;          /* in zephyr/dts/arm/armv8-m.dtsi:18 */
			arm,num-irq-priority-bits = < 0x3 >; /* in zephyr/dts/arm/nxp/nxp_lpc55S1x_common.dtsi:341 */
			phandle = < 0x1 >;                   /* in zephyr/dts/arm/armv8-m.dtsi:10 */
		};

		/* node '/soc/timer@e000e010' defined in zephyr/dts/arm/armv8-m.dtsi:21 */
		systick: timer@e000e010 {
			compatible = "arm,armv8m-systick"; /* in zephyr/dts/arm/armv8-m.dtsi:22 */
			reg = < 0xe000e010 0x10 >;         /* in zephyr/dts/arm/armv8-m.dtsi:23 */
		};
	};

	/* node '/chosen' defined in zephyr/dts/common/skeleton.dtsi:13 */
	chosen {
		zephyr,sram = &sram0;                     /* in zephyr/boards/nxp/lpcxpresso55s16/lpcxpresso55s16_common.dtsi:14 */
		zephyr,flash = &flash0;                   /* in zephyr/boards/nxp/lpcxpresso55s16/lpcxpresso55s16_common.dtsi:15 */
		zephyr,code-partition = &slot0_partition; /* in zephyr/boards/nxp/lpcxpresso55s16/lpcxpresso55s16_common.dtsi:16 */
		zephyr,uart-mcumgr = &flexcomm0;          /* in zephyr/boards/nxp/lpcxpresso55s16/lpcxpresso55s16_common.dtsi:17 */
		zephyr,console = &flexcomm0;              /* in zephyr/boards/nxp/lpcxpresso55s16/lpcxpresso55s16_common.dtsi:18 */
		zephyr,shell-uart = &flexcomm0;           /* in zephyr/boards/nxp/lpcxpresso55s16/lpcxpresso55s16_common.dtsi:19 */
		zephyr,entropy = &rng;                    /* in zephyr/boards/nxp/lpcxpresso55s16/lpcxpresso55s16_common.dtsi:20 */
		zephyr,canbus = &can0;                    /* in zephyr/boards/nxp/lpcxpresso55s16/lpcxpresso55s16_common.dtsi:21 */
		zephyr,flash-controller = &iap;           /* in zephyr/boards/nxp/lpcxpresso55s16/lpcxpresso55s16_common.dtsi:22 */
	};

	/* node '/aliases' defined in zephyr/dts/common/skeleton.dtsi:15 */
	aliases {
		led0 = &red_led;           /* in zephyr/boards/nxp/lpcxpresso55s16/lpcxpresso55s16_common.dtsi:26 */
		led1 = &green_led;         /* in zephyr/boards/nxp/lpcxpresso55s16/lpcxpresso55s16_common.dtsi:27 */
		led2 = &blue_led;          /* in zephyr/boards/nxp/lpcxpresso55s16/lpcxpresso55s16_common.dtsi:28 */
		sw0 = &btn_wk;             /* in zephyr/boards/nxp/lpcxpresso55s16/lpcxpresso55s16_common.dtsi:29 */
		sw1 = &btn_usr;            /* in zephyr/boards/nxp/lpcxpresso55s16/lpcxpresso55s16_common.dtsi:30 */
		sw2 = &btn_isp;            /* in zephyr/boards/nxp/lpcxpresso55s16/lpcxpresso55s16_common.dtsi:31 */
		usart-0 = &flexcomm0;      /* in zephyr/boards/nxp/lpcxpresso55s16/lpcxpresso55s16_common.dtsi:32 */
		magn0 = &fxos8700;         /* in zephyr/boards/nxp/lpcxpresso55s16/lpcxpresso55s16_common.dtsi:33 */
		accel0 = &fxos8700;        /* in zephyr/boards/nxp/lpcxpresso55s16/lpcxpresso55s16_common.dtsi:34 */
		mcuboot-button0 = &btn_wk; /* in zephyr/boards/nxp/lpcxpresso55s16/lpcxpresso55s16_common.dtsi:35 */
	};

	/* node '/cpus' defined in zephyr/dts/arm/nxp/nxp_lpc55S1x_common.dtsi:17 */
	cpus {
		#address-cells = < 0x1 >; /* in zephyr/dts/arm/nxp/nxp_lpc55S1x_common.dtsi:18 */
		#size-cells = < 0x0 >;    /* in zephyr/dts/arm/nxp/nxp_lpc55S1x_common.dtsi:19 */

		/* node '/cpus/cpu@0' defined in zephyr/dts/arm/nxp/nxp_lpc55S1x_common.dtsi:21 */
		cpu@0 {
			compatible = "arm,cortex-m33f"; /* in zephyr/dts/arm/nxp/nxp_lpc55S1x_common.dtsi:22 */
			reg = < 0x0 >;                  /* in zephyr/dts/arm/nxp/nxp_lpc55S1x_common.dtsi:23 */
			#address-cells = < 0x1 >;       /* in zephyr/dts/arm/nxp/nxp_lpc55S1x_common.dtsi:24 */
			#size-cells = < 0x1 >;          /* in zephyr/dts/arm/nxp/nxp_lpc55S1x_common.dtsi:25 */

			/* node '/cpus/cpu@0/mpu@e000ed90' defined in zephyr/dts/arm/nxp/nxp_lpc55S1x_common.dtsi:27 */
			mpu: mpu@e000ed90 {
				compatible = "arm,armv8m-mpu"; /* in zephyr/dts/arm/nxp/nxp_lpc55S1x_common.dtsi:28 */
				reg = < 0xe000ed90 0x40 >;     /* in zephyr/dts/arm/nxp/nxp_lpc55S1x_common.dtsi:29 */
			};
		};
	};

	/* node '/leds' defined in zephyr/boards/nxp/lpcxpresso55s16/lpcxpresso55s16_common.dtsi:38 */
	leds {
		compatible = "gpio-leds"; /* in zephyr/boards/nxp/lpcxpresso55s16/lpcxpresso55s16_common.dtsi:39 */

		/* node '/leds/led_0' defined in zephyr/boards/nxp/lpcxpresso55s16/lpcxpresso55s16_common.dtsi:41 */
		red_led: led_0 {
			gpios = < &gpio1 0x4 0x0 >; /* in zephyr/boards/nxp/lpcxpresso55s16/lpcxpresso55s16_common.dtsi:42 */
			label = "Red LED";          /* in zephyr/boards/nxp/lpcxpresso55s16/lpcxpresso55s16_common.dtsi:43 */
		};

		/* node '/leds/led_1' defined in zephyr/boards/nxp/lpcxpresso55s16/lpcxpresso55s16_common.dtsi:46 */
		green_led: led_1 {
			gpios = < &gpio1 0x7 0x0 >; /* in zephyr/boards/nxp/lpcxpresso55s16/lpcxpresso55s16_common.dtsi:47 */
			label = "Green LED";        /* in zephyr/boards/nxp/lpcxpresso55s16/lpcxpresso55s16_common.dtsi:48 */
		};

		/* node '/leds/led_2' defined in zephyr/boards/nxp/lpcxpresso55s16/lpcxpresso55s16_common.dtsi:51 */
		blue_led: led_2 {
			gpios = < &gpio1 0x6 0x0 >; /* in zephyr/boards/nxp/lpcxpresso55s16/lpcxpresso55s16_common.dtsi:52 */
			label = "Blue LED";         /* in zephyr/boards/nxp/lpcxpresso55s16/lpcxpresso55s16_common.dtsi:53 */
		};
	};

	/* node '/gpio_keys' defined in zephyr/boards/nxp/lpcxpresso55s16/lpcxpresso55s16_common.dtsi:57 */
	gpio_keys {
		compatible = "gpio-keys"; /* in zephyr/boards/nxp/lpcxpresso55s16/lpcxpresso55s16_common.dtsi:58 */

		/* node '/gpio_keys/button_0' defined in zephyr/boards/nxp/lpcxpresso55s16/lpcxpresso55s16_common.dtsi:60 */
		btn_wk: button_0 {
			label = "Wakeup button";     /* in zephyr/boards/nxp/lpcxpresso55s16/lpcxpresso55s16_common.dtsi:61 */
			gpios = < &gpio1 0x12 0x1 >; /* in zephyr/boards/nxp/lpcxpresso55s16/lpcxpresso55s16_common.dtsi:62 */
			zephyr,code = < 0x8f >;      /* in zephyr/boards/nxp/lpcxpresso55s16/lpcxpresso55s16_common.dtsi:63 */
		};

		/* node '/gpio_keys/button_1' defined in zephyr/boards/nxp/lpcxpresso55s16/lpcxpresso55s16_common.dtsi:66 */
		btn_usr: button_1 {
			label = "USR button";       /* in zephyr/boards/nxp/lpcxpresso55s16/lpcxpresso55s16_common.dtsi:67 */
			gpios = < &gpio1 0x9 0x1 >; /* in zephyr/boards/nxp/lpcxpresso55s16/lpcxpresso55s16_common.dtsi:68 */
			zephyr,code = < 0xb >;      /* in zephyr/boards/nxp/lpcxpresso55s16/lpcxpresso55s16_common.dtsi:69 */
		};

		/* node '/gpio_keys/button_2' defined in zephyr/boards/nxp/lpcxpresso55s16/lpcxpresso55s16_common.dtsi:72 */
		btn_isp: button_2 {
			label = "ISP button";       /* in zephyr/boards/nxp/lpcxpresso55s16/lpcxpresso55s16_common.dtsi:73 */
			gpios = < &gpio0 0x5 0x1 >; /* in zephyr/boards/nxp/lpcxpresso55s16/lpcxpresso55s16_common.dtsi:74 */
			zephyr,code = < 0x2 >;      /* in zephyr/boards/nxp/lpcxpresso55s16/lpcxpresso55s16_common.dtsi:75 */
		};
	};

	/* node '/mikrobus-connector' defined in zephyr/boards/nxp/lpcxpresso55s16/lpcxpresso55s16_common.dtsi:79 */
	mikrobus_header: mikrobus-connector {
		compatible = "mikro-bus";                  /* in zephyr/boards/nxp/lpcxpresso55s16/lpcxpresso55s16_common.dtsi:80 */
		#gpio-cells = < 0x2 >;                     /* in zephyr/boards/nxp/lpcxpresso55s16/lpcxpresso55s16_common.dtsi:81 */
		gpio-map-mask = < 0xffffffff 0xffffffc0 >; /* in zephyr/boards/nxp/lpcxpresso55s16/lpcxpresso55s16_common.dtsi:82 */
		gpio-map-pass-thru = < 0x0 0x3f >;         /* in zephyr/boards/nxp/lpcxpresso55s16/lpcxpresso55s16_common.dtsi:83 */
		gpio-map = < 0x0 0x0 &gpio0 0x10 0x0 >,
		           < 0x2 0x0 &gpio1 0x1 0x0 >,
		           < 0x3 0x0 &gpio1 0x2 0x0 >,
		           < 0x4 0x0 &gpio1 0x3 0x0 >,
		           < 0x5 0x0 &gpio0 0x1a 0x0 >,
		           < 0x6 0x0 &gpio1 0x5 0x0 >,
		           < 0x7 0x0 &gpio1 0x12 0x0 >,
		           < 0x8 0x0 &gpio1 0x18 0x0 >,
		           < 0x9 0x0 &gpio0 0x1b 0x0 >,
		           < 0xa 0x0 &gpio1 0x14 0x0 >,
		           < 0xb 0x0 &gpio1 0x15 0x0 >;    /* in zephyr/boards/nxp/lpcxpresso55s16/lpcxpresso55s16_common.dtsi:84 */
	};

	/* node '/arduino-connector' defined in zephyr/boards/nxp/lpcxpresso55s16/lpcxpresso55s16_common.dtsi:102 */
	arduino_header: arduino-connector {
		compatible = "arduino-header-r3";          /* in zephyr/boards/nxp/lpcxpresso55s16/lpcxpresso55s16_common.dtsi:103 */
		#gpio-cells = < 0x2 >;                     /* in zephyr/boards/nxp/lpcxpresso55s16/lpcxpresso55s16_common.dtsi:104 */
		gpio-map-mask = < 0xffffffff 0xffffffc0 >; /* in zephyr/boards/nxp/lpcxpresso55s16/lpcxpresso55s16_common.dtsi:105 */
		gpio-map-pass-thru = < 0x0 0x3f >;         /* in zephyr/boards/nxp/lpcxpresso55s16/lpcxpresso55s16_common.dtsi:106 */
		gpio-map = < 0x0 0x0 &gpio0 0x10 0x0 >,
		           < 0x1 0x0 &gpio0 0x17 0x0 >,
		           < 0x2 0x0 &gpio0 0x0 0x0 >,
		           < 0x4 0x0 &gpio0 0xd 0x0 >,
		           < 0x5 0x0 &gpio0 0xe 0x0 >,
		           < 0x6 0x0 &gpio1 0x18 0x0 >,
		           < 0x7 0x0 &gpio0 0x1b 0x0 >,
		           < 0x8 0x0 &gpio0 0xf 0x0 >,
		           < 0x9 0x0 &gpio1 0x6 0x0 >,
		           < 0xa 0x0 &gpio1 0x7 0x0 >,
		           < 0xb 0x0 &gpio1 0x4 0x0 >,
		           < 0xc 0x0 &gpio1 0xa 0x0 >,
		           < 0xd 0x0 &gpio1 0x9 0x0 >,
		           < 0xe 0x0 &gpio1 0x8 0x0 >,
		           < 0xf 0x0 &gpio1 0x5 0x0 >,
		           < 0x10 0x0 &gpio1 0x1 0x0 >,
		           < 0x11 0x0 &gpio0 0x1a 0x0 >,
		           < 0x12 0x0 &gpio1 0x3 0x0 >,
		           < 0x13 0x0 &gpio1 0x2 0x0 >,
		           < 0x14 0x0 &gpio1 0x15 0x0 >,
		           < 0x15 0x0 &gpio1 0x14 0x0 >;   /* in zephyr/boards/nxp/lpcxpresso55s16/lpcxpresso55s16_common.dtsi:107 */
	};
};
